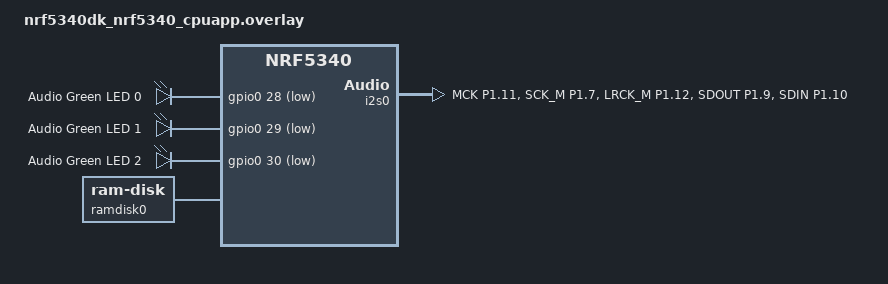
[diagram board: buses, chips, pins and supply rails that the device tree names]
/*
 * Copyright (c) 2024 Nordic Semiconductor ASA
 *
 * SPDX-License-Identifier: LicenseRef-Nordic-5-Clause
 */

/ {
	audioleds: audioleds {
		compatible = "gpio-leds";
		status = "okay";

		led_conn_status: led_conn_status {
			gpios = <&gpio0 28 GPIO_ACTIVE_LOW>;
			label = "Audio Green LED 0";
		};

		led_sync_status: led_sync_status {
			gpios = <&gpio0 29 GPIO_ACTIVE_LOW>;
			label = "Audio Green LED 1";
		};

		led_app_status: led_app_status {
			gpios = <&gpio0 30 GPIO_ACTIVE_LOW>;
			label = "Audio Green LED 2";
		};
	};

	/* Minimal ramdisk required by FatFS (FF_VOLUMES >= 1).
	 * 2 sectors x 512 bytes = 1024 bytes of RAM.
	 * Not used functionally; satisfies the build constraint. */
	ramdisk0: ramdisk0 {
		compatible = "zephyr,ram-disk";
		disk-name = "RAM";
		sector-size = <512>;
		sector-count = <2>;
	};

};

&pinctrl {
	i2s0_default: i2s0_default {
		group1 {
			psels = <NRF_PSEL(I2S_MCK, 1, 11)>;
			nordic,drive-mode = <NRF_DRIVE_H0H1>;
		};

		group2 {
			psels = <NRF_PSEL(I2S_SCK_M, 1, 7)>,
			<NRF_PSEL(I2S_LRCK_M, 1, 12)>,
			<NRF_PSEL(I2S_SDOUT, 1, 9)>,
			<NRF_PSEL(I2S_SDIN, 1, 10)>;
		};
	};

	i2s0_sleep: i2s0_sleep {
		group1 {
			psels = <NRF_PSEL(I2S_MCK, 1, 11)>,
			<NRF_PSEL(I2S_SCK_M, 1, 7)>,
			<NRF_PSEL(I2S_LRCK_M, 1, 12)>,
			<NRF_PSEL(I2S_SDOUT, 1, 9)>,
			<NRF_PSEL(I2S_SDIN, 1, 10)>;
			low-power-enable;
		};
	};
};

&i2s0 {
	compatible = "nordic,nrf-i2s";
	status = "okay";
	pinctrl-0 = <&i2s0_default>;
	pinctrl-1 = <&i2s0_sleep>;
	pinctrl-names = "default", "sleep";
};

/*
 * GPIO Forwarder — nRF21540 FEM (BT40NE/Fanstel)
 *
 * En nRF5340, los pins GPIO están controlados por el app core.
 * El network core (ipc_radio/MPSL) los accede via el driver gpio_fwd,
 * que reenvía las llamadas GPIO del net core al app core por IPC.
 * Sin este bloque, TX_EN/RX_EN/PDN nunca se activan físicamente
 * aunque MPSL crea que los controla → nRF21540 en power-down → -15dBm.
 *
 * Inocuo en el build DK: los pines quedan disponibles pero nadie los usa
 * desde la net core (ipc_radio DK no tiene FEM configurado).
 */
&gpio_fwd {
	nrf21540-gpio-if {
		gpios = <&gpio0 21 0>,  /* TX_EN  = P0.21 */
		        <&gpio0 27 0>,  /* RX_EN  = P0.27 */
		        <&gpio0 26 0>,  /* PDN    = P0.26 */
		        <&gpio1 5  0>,  /* ANT_SEL= P1.05 */
		        <&gpio1 4  0>;  /* MODE   = P1.04 */
	};
};
